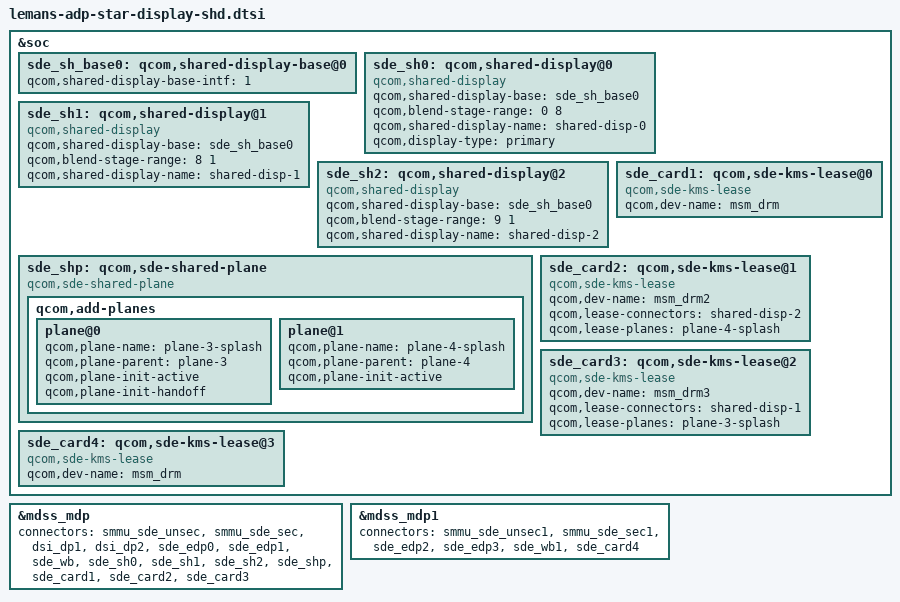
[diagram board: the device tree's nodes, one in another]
&soc {
	sde_sh_base0: qcom,shared-display-base@0 {
		qcom,shared-display-base-intf = <1>;
	};

	sde_sh0: qcom,shared-display@0 {
		compatible = "qcom,shared-display";
		qcom,shared-display-base = <&sde_sh_base0>;
		qcom,blend-stage-range = <0 8>;
		qcom,shared-display-name = "shared-disp-0";
		qcom,display-type = "primary";
	};

	sde_sh1: qcom,shared-display@1 {
		compatible = "qcom,shared-display";
		qcom,shared-display-base = <&sde_sh_base0>;
		qcom,blend-stage-range = <8 1>;
		qcom,shared-display-name = "shared-disp-1";
        };


	sde_sh2: qcom,shared-display@2 {
		compatible = "qcom,shared-display";
		qcom,shared-display-base = <&sde_sh_base0>;
		qcom,blend-stage-range = <9 1>;
		qcom,shared-display-name = "shared-disp-2";
        };

	sde_shp: qcom,sde-shared-plane {
		compatible = "qcom,sde-shared-plane";
		qcom,add-planes {
			plane@0 {
				qcom,plane-name = "plane-3-splash";
				qcom,plane-parent = "plane-3";
				qcom,plane-init-active;
				qcom,plane-init-handoff;
			};
			plane@1 {
				qcom,plane-name = "plane-4-splash";
				qcom,plane-parent = "plane-4";
				qcom,plane-init-active;
			};
		};
	};

        sde_card1: qcom,sde-kms-lease@0 {
		compatible = "qcom,sde-kms-lease";
		qcom,dev-name = "msm_drm";
	};

        sde_card2: qcom,sde-kms-lease@1 {
		compatible = "qcom,sde-kms-lease";
		qcom,dev-name = "msm_drm2";
		qcom,lease-connectors = "shared-disp-2";
		qcom,lease-planes = "plane-4-splash";
	};

	sde_card3: qcom,sde-kms-lease@2 {
		compatible = "qcom,sde-kms-lease";
		qcom,dev-name = "msm_drm3";
		qcom,lease-connectors = "shared-disp-1";
		qcom,lease-planes = "plane-3-splash";
	};

	sde_card4: qcom,sde-kms-lease@3 {
		compatible = "qcom,sde-kms-lease";
		qcom,dev-name = "msm_drm";
	};

};

&mdss_mdp {
	connectors = <&smmu_sde_unsec &smmu_sde_sec &dsi_dp1 &dsi_dp2
				&sde_edp0 &sde_edp1 &sde_wb
                                &sde_sh0 &sde_sh1 &sde_sh2 &sde_shp
				&sde_card1 &sde_card2 &sde_card3>;
};

&mdss_mdp1 {
	connectors = <&smmu_sde_unsec1 &smmu_sde_sec1
				&sde_edp2 &sde_edp3 &sde_wb1
				&sde_card4>;
};
